# R7FA6T2BD register map
Vendor: Renesas Electronics Corporation; Series: RA6; File version: 1.30.01
CPU: CM33 r0p4, little endian, MPU, FPU, VTOR, 4 interrupt priority bits, 96 interrupts
Registers are 32-bit, read-write, reset 0x0 unless marked. A register's access mark holds for its fields unless they carry their own. Offsets are from the block's base; [hi:lo] are bit positions; {n}, {i} and the like mark numbered series.

## IIC_B0 — Inter-Integrated Circuit 0
Base 0x4011F000
Same registers: IIC_B1 0x4011F400
0x14 BCTL — Bus Control Register
  [31] BUSE — Bus Enable
    0=IIC bus operation is disabled; 1=IIC bus operation is enabled
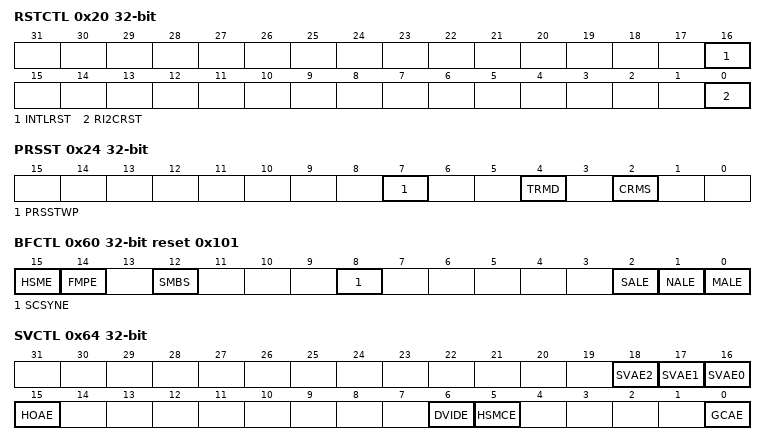
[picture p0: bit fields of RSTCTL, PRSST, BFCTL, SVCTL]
0x20 RSTCTL — Reset Control Register
  [16] INTLRST — Internal Software Reset
    0=Releases of some registers and internal state; 1=Resets of some registers and internal state
  [0] RI2CRST — IIC Software Reset
    0=Reset of all registers and internal state; 1=Releases of all registers and internal state
0x24 PRSST — Present State Register
  [7] PRSSTWP wo — Present State Write Protect
    0=CRMS bit is protected; 1=CRMS bit can be written when writing simultaneously with the value of the target bit
  [4] TRMD ro — Transmit/Receive Mode
    0=Receive mode; 1=Transmit mode
  [2] CRMS — Current Master
    0=The Master is not the Current Master, and must request and acquire bus ownership before initiating any transfer; 1=The Master is the Current Master, and as a result can initiate transfers
0x60 BFCTL reset 0x101 — Bus Function Control Register
  [15] HSME — High Speed Mode Enable
    0=Disable High Speed Mode; 1=Enable High Speed Mode
  [14] FMPE — Fast-mode Plus Enable
    0=No Fm+ slope control circuit uses for the SCLn pin and SDAn pin. (n = 0, 1); 1=An Fm+ slope control circuit uses for the SCLn pin and SDAn pin. (n = 0, 1)
  [12] SMBS — SMBus/I2C Bus Selection
    0=The I2C bus select; 1=The SMBus select
  [8] SCSYNE — SCL Synchronous Circuit Enable
    0=No SCL synchronous circuit uses; 1=An SCL synchronous circuit uses
  [2] SALE — Slave Arbitration-Lost Detection Enable
    0=Slave arbitration-lost detection disables; 1=Slave arbitration-lost detection enables
  [1] NALE — NACK Transmission Arbitration-Lost Detection Enable
    0=NACK transmission arbitration-lost detection disables; 1=NACK transmission arbitration-lost detection enables
  [0] MALE — Master Arbitration-Lost Detection Enable
    0=Master arbitration-lost detection disables. Disables the arbitration-lost detection function and does not clear the CRMS and TRMD bits in PRSST automatically when arbitration is lost.; 1=Master arbitration-lost detection enables. Enables the arbitration-lost detection function and clears the CRMS and TRMD bits in PRSST automatically when arbitration is lost.
0x64 SVCTL — Slave Control Register
  [18] SVAE2 — Slave Address Enable 2
    0=Slave 2 disables; 1=Slave 2 enables
  [17] SVAE1 — Slave Address Enable 1
    0=Slave 1 disables; 1=Slave 1 enables
  [16] SVAE0 — Slave Address Enable 0
    0=Slave 0 disables; 1=Slave 0 enables
  [15] HOAE — Host Address Enable
    0=Host address detection disables; 1=Host address detection enables
  [6] DVIDE — Device-ID Address Enable
    0=Device-ID address detection disables; 1=Device-ID address detection enables
  [5] HSMCE — Hs-mode Master Code Enable
    0=Hs-mode Master Code Detection disables; 1=Hs-mode Master Code Detection enables
  [0] GCAE — General Call Address Enable
    0=General call address detection disables; 1=General call address detection enables
0x70 REFCKCTL — Reference Clock Control Register
  [2:0] IREFCKS — Internal Reference Clock Selection
    0=IICCLK/1 clock; 1=IICCLK/2 clock; 2=IICCLK/4 clock; 3=IICCLK/8 clock; 4=IICCLK/16 clock; 5=IICCLK/32 clock; 6=IICCLK/64 clock; 7=IICCLK/128 clock
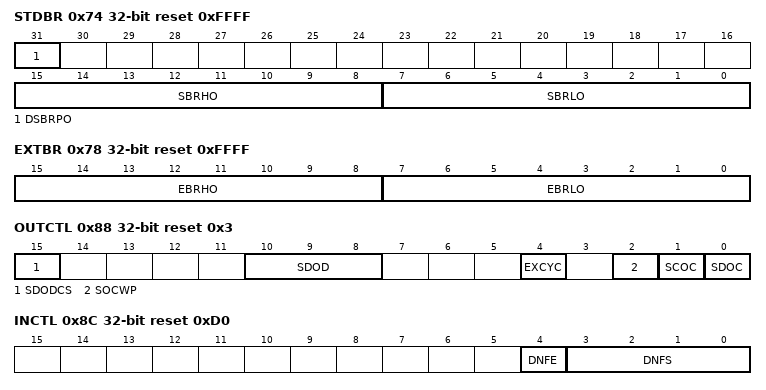
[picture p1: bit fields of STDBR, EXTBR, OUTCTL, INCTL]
0x74 STDBR reset 0xFFFF — Standard Bit Rate Register
  [31] DSBRPO — Double the Standard Bit Rate Period for Open-Drain
    0=The time period set for SBRHO[7:0] and SBRLO[7:0] is not doubled; 1=The time period set for SBRHO[7:0] and SBRLO[7:0] is doubled
  [15:8] SBRHO — Count value of the High-level period of SCL clock
  [7:0] SBRLO — Count value of the Low-level period of SCL clock
0x78 EXTBR reset 0xFFFF — Extended Bit Rate Register
  [15:8] EBRHO — Extended Bit Rate High-Level Period Open-Drain
  [7:0] EBRLO — Extended Bit Rate Low-Level Period Open-Drain
0x7C BFRECDT — Bus Free Condition Detection Time Register
  [8:0] FRECYC — Bus Free Condition Detection Cycle
0x88 OUTCTL reset 0x3 — Output Control Register
  [15] SDODCS — SDA Output Delay Clock Source Selection
    0=The internal reference clock (IICφ) is selected as the clock source of the SDA output delay counter; 1=The internal reference clock divided by 2 (IICφ/2) is selected as the clock source of the SDA output delay counter
  [10:8] SDOD — SDA Output Delay
    0=No output delay; 1=1 IICφ cycle (When OUTCTL.SDODCS = 0 (IICφ)) 1 or 2 IICφ cycles (When OUTCTL.SDODCS = 1 (IICφ/2)); 2=2 IICφ cycles (When OUTCTL.SDODCS = 0 (IICφ)) 3 or 4 IICφ cycles (When OUTCTL.SDODCS = 1 (IICφ/2)); 3=3 IICφ cycles (When OUTCTL.SDODCS = 0 (IICφ)) 5 or 6 IICφ cycles (When OUTCTL.SDODCS = 1 (IICφ/2)); 4=4 IICφ cycles (When OUTCTL.SDODCS = 0 (IICφ)) 7 or 8 IICφ cycles (When OUTCTL.SDODCS = 1 (IICφ/2)); 5=5 IICφ cycles (When OUTCTL.SDODCS = 0 (IICφ)) 9 or 10 IICφ cycles (When OUTCTL.SDODCS = 1 (IICφ/2)); 6=6 IICφ cycles (When OUTCTL.SDODCS = 0 (IICφ)) 11 or 12 IICφ cycles (When OUTCTL.SDODCS = 1 (IICφ/2)); 7=7 IICφ cycles (When OUTCTL.SDODCS = 0 (IICφ)) 13 or 14 IICφ cycles (When OUTCTL.SDODCS = 1 (IICφ/2))
  [4] EXCYC — Extra SCL Clock Cycle Output
    0=Does not output an extra SCL clock cycle (default); 1=Outputs an extra SCL clock cycle
  [2] SOCWP wo — SCL/SDA Output Control Write Protect
    0=Bits SCOC and SDOC are protected; 1=Bits SCOC and SDOC can be written (When writing simultaneously with the value of the target bit). This bit is read as 0.
  [1] SCOC — SCL Output Control
    0=IIC drives the SCLn pin low; 1=IIC releases the SCLn pin
  [0] SDOC — SDA Output Control
    0=IIC drives the SDAn pin low; 1=IIC releases the SDAn pin
0x8C INCTL reset 0xD0 — Input Control Register
  [4] DNFE — Digital Noise Filter Circuit Enable
    0=No digital noise filter circuit is used; 1=A digital noise filter circuit is used
  [3:0] DNFS — Digital Noise Filter Stage Selection
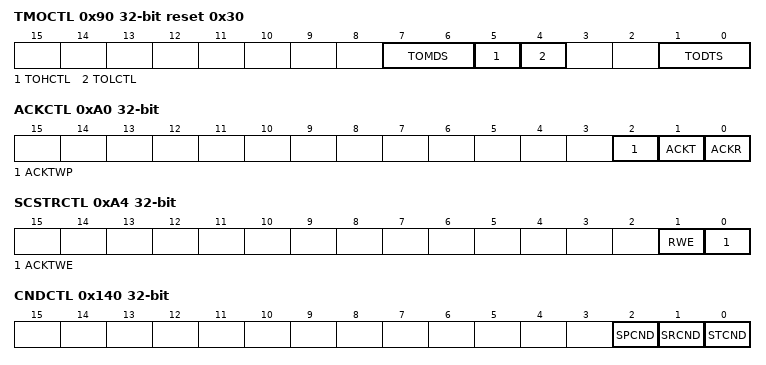
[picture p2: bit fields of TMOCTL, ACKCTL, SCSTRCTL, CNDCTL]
0x90 TMOCTL reset 0x30 — Timeout Control Register
  [7:6] TOMDS — Timeout Operation Mode Selection
    0=Timeout is detected during the following conditions: The bus is busy (BCST.BFREF = 0) in master mode.IIC’s own slave address is detected and the bus is busy in slave mode.The bus is free (BCST.BFREF = 1) while generation of a START condition is requested (CNDCTL.STCND = 1); 1=Timeout is detected while the bus is busy; 2=Timeout is detected while the bus is free; 3=Setting prohibited
  [5] TOHCTL — Timeout H Count Control
    0=Count is disabled while the SCLn line is at a high level; 1=Count is enabled while the SCLn line is at a high level
  [4] TOLCTL — Timeout L Count Control
    0=Count is disabled while the SCLn line is at a low level; 1=Count is enabled while the SCLn line is at a low level
  [1:0] TODTS — Timeout Detection Time Selection
    0=16bit-timeout; 1=14bit-timeout; 2=8bit-timeout; 3=6bit-timeout
0xA0 ACKCTL — Acknowledge Control Register
  [2] ACKTWP wo — ACKT Write Protect
    0=The ACKT bit are protected; 1=The ACKT bit can be written (when writing simultaneously with the value of the target bit). This bit is read as 0.
  [1] ACKT — Acknowledge Transmission
    0=A 0 is sent as the acknowledge bit (ACK transmission); 1=A 1 is sent as the acknowledge bit (NACK transmission)
  [0] ACKR ro — Acknowledge Reception
    0=A 0 is received as the acknowledge bit (ACK reception); 1=A 1 is received as the acknowledge bit (NACK reception)
0xA4 SCSTRCTL — SCL Stretch Control Register
  [1] RWE — Receive Wait Enable
    0=No WAIT (The period between ninth clock cycle and first clock cycle is not held low.); 1=WAIT (The period between ninth clock cycle and first clock cycle is held low.) Low-hold is released by reading NTDTBP0
  [0] ACKTWE — Acknowledge Transmission Wait Enable
    0=NTST.RDBFF0 is set at the rising edge of the ninth SCL clock cycle. (The SCLn line is not held low at the falling edge of the eighth clock cycle.); 1=NTST.RDBFF0 is set at the rising edge of the eighth SCL clock cycle. (The SCLn line is held low at the falling edge of the eighth clock cycle.) Low-hold is released by writing a value to the ACKCTL.ACKT bit.
0x140 CNDCTL — Condition Control Register
  [2] SPCND — STOP (P) Condition Issuance
    0=Does not request to issue a STOP condition; 1=Requests to issue a STOP condition
  [1] SRCND — Repeated START (Sr) Condition Issuance
    0=Does not request to issue a Repeated START condition; 1=Requests to issue a Repeated START condition
  [0] STCND — START (S) Condition Issuance
    0=Does not request to issue a START condition; 1=Requests to issue a START condition
0x158 NTDTBP0 — Normal Transfer Data Buffer Port Register 0
0x158 NTDTBP0_BY 8-bit (alternate view of NTDTBP0) — Normal Transfer Data Buffer Port Register 0
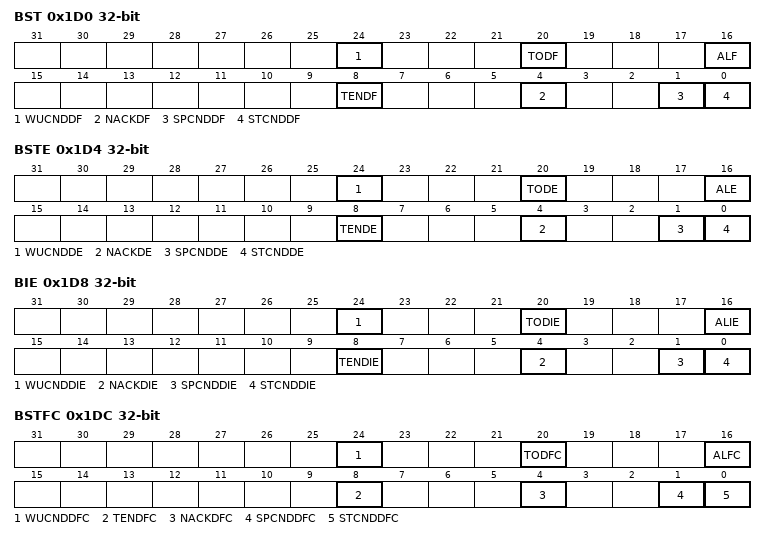
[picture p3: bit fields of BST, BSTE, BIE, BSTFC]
0x1D0 BST — Bus Status Register
  [24] WUCNDDF — Wake-Up Condition Detection Flag
    0=Wake-Up is not detected; 1=Wake-Up is detected
  [20] TODF — Timeout Detection Flag
    0=Timeout is not detected; 1=Timeout is detected
  [16] ALF — Arbitration Lost Flag
    0=Arbitration is not lost; 1=Arbitration is lost
  [8] TENDF — Transmit End Flag
    0=Data is being transmitted; 1=Data has been transmitted
  [4] NACKDF — NACK Detection Flag
    0=NACK is not detected; 1=NACK is detected
  [1] SPCNDDF — STOP Condition Detection Flag
    0=STOP condition is not detected; 1=STOP condition is detected
  [0] STCNDDF — START Condition Detection Flag
    0=START condition is not detected; 1=START condition is detected
0x1D4 BSTE — Bus Status Enable Register
  [24] WUCNDDE — Wake-up Condition Detection Enable
    0=Disables Wake-up Condition Detection Status logging; 1=Enables Wake-up Condition Detection Status logging
  [20] TODE — Timeout Detection Enable
    0=Disables Timeout Detection Interrupt Status logging; 1=Enables Timeout Detection Interrupt Status logging
  [16] ALE — Arbitration Lost Enable
    0=Disables Arbitration Lost Interrupt Status logging; 1=Enables Arbitration Lost Interrupt Status logging
  [8] TENDE — Transmit End Enable
    0=Disables Transmit End Interrupt Status logging; 1=Enables Transmit End Interrupt Status logging
  [4] NACKDE — NACK Detection Enable
    0=Disables NACK Detection Interrupt Status logging; 1=Enables NACK Detection Interrupt Status logging
  [1] SPCNDDE — STOP Condition Detection Enable
    0=Disables STOP condition Detection Interrupt Status logging; 1=Enables STOP condition Detection Interrupt Status logging
  [0] STCNDDE — START Condition Detection Enable
    0=Disables START condition Detection Interrupt Status logging; 1=Enables START condition Detection Interrupt Status logging
0x1D8 BIE — Bus Interrupt Enable Register
  [24] WUCNDDIE — Wake-Up Condition Detection Interrupt Enable
    0=Disables Wake-Up Condition Detection Interrupt Signal; 1=Enables Wake-Up Condition Detection Interrupt Signal
  [20] TODIE — Timeout Detection Interrupt Enable
    0=Disables Timeout Detection Interrupt Signal; 1=Enables Timeout Detection Interrupt Signal
  [16] ALIE — Arbitration Lost Interrupt Enable
    0=Disables Arbitration Lost Interrupt Signal; 1=Enables Arbitration Lost Interrupt Signal
  [8] TENDIE — Transmit End Interrupt Enable
    0=Disables Transmit End Interrupt Signal; 1=Enables Transmit End Interrupt Signal
  [4] NACKDIE — NACK Detection Interrupt Enable
    0=Disables NACK Detection Interrupt Signal; 1=Enables NACK Detection Interrupt Signal
  [1] SPCNDDIE — STOP Condition Detection Interrupt Enable
    0=Disables STOP condition Detection Interrupt Signal; 1=Enables STOP condition Detection Interrupt Signal
  [0] STCNDDIE — START Condition Detection Interrupt Enable
    0=Disables START condition Detection Interrupt Signal; 1=Enables START condition Detection Interrupt Signal
0x1DC BSTFC — Bus Status Force Register
  [24] WUCNDDFC wo — Wake-Up Condition Detection Force
    0=Not Force Wake-Up Condition Detection Interrupt for software testing; 1=Force Wake-Up Condition Detection Interrupt for software testing
  [20] TODFC wo — Timeout Detection Force
    0=Not Force Timeout Detection Interrupt for software testing; 1=Force Timeout Detection Interrupt for software testing
  [16] ALFC wo — Arbitration Lost Force
    0=Not Force Arbitration Lost Interrupt for software testing; 1=Force Arbitration Lost Interrupt for software testing
  [8] TENDFC wo — Transmit End Force
    0=Not Force Transmit End Interrupt for software testing; 1=Force Transmit End Interrupt for software testing
  [4] NACKDFC wo — NACK Detection Force
    0=Not Force NACK Detection Interrupt for software testing; 1=Force NACK Detection Interrupt for software testing
  [1] SPCNDDFC wo — STOP condition Detection Force
    0=Not Force STOP condition Detection Interrupt for software testing; 1=Force STOP condition Detection Interrupt for software testing
  [0] STCNDDFC wo — START condition Detection Force
    0=Not Force START condition Detection Interrupt for software testing; 1=Force START condition Detection Interrupt for software testing
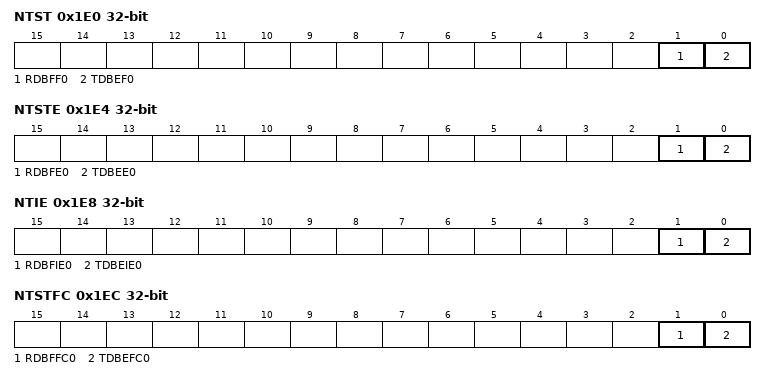
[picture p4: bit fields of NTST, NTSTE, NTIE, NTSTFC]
0x1E0 NTST — Normal Transfer Status Register
  [1] RDBFF0 — Normal Receive Data Buffer Full Flag 0
    0=Normal Receive Data Buffer0 contains no receive data; 1=Normal Receive Data Buffer0 contains receive data
  [0] TDBEF0 — Normal Transmit Data Buffer Empty Flag 0
    0=Normal Transmit Data Buffer 0 contains transmit data; 1=Normal Transmit Data Buffer 0 contains no transmit data
0x1E4 NTSTE — Normal Transfer Status Enable Register
  [1] RDBFE0 — Normal Receive Data Buffer Full Enable 0
    0=Disables Rx0 Data Buffer Full Interrupt Status logging; 1=Enables Rx0 Data Buffer Full Interrupt Status logging
  [0] TDBEE0 — Normal Transmit Data Buffer Empty Enable 0
    0=Disables Tx0 Data Buffer Empty Interrupt Status logging; 1=Enables Tx0 Data Buffer Empty Interrupt Status logging
0x1E8 NTIE — Normal Transfer Interrupt Enable Register
  [1] RDBFIE0 — Normal Receive Data Buffer Full Interrupt Enable 0
    0=Disables Rx0 Data Buffer Full Interrupt Signal; 1=Enables Rx0 Data Buffer Full Interrupt Signal
  [0] TDBEIE0 — Normal Transmit Data Buffer Empty Interrupt Enable 0
    0=Disables Tx0 Data Buffer Empty Interrupt Signal; 1=Enables Tx0 Data Buffer Empty Interrupt Signal
0x1EC NTSTFC wo — Normal Transfer Status Force Register
  [1] RDBFFC0 — Normal Receive Data Buffer Full Force 0
    0=Not Force Rx0 Data Buffer Full Interrupt for software testing; 1=Force Rx0 Data Buffer Full Interrupt for software testing
  [0] TDBEFC0 — Normal Transmit Data Buffer Empty Force 0
    0=Not Force Tx0 Data Buffer Empty Interrupt for software testing; 1=Force Tx0 Data Buffer Empty Interrupt for software testing
0x210 BCST ro — Bus Condition Status Register
  [0] BFREF — Bus Free Detection Flag
    0=Have not Detected Bus Free; 1=Have Detected Bus Free
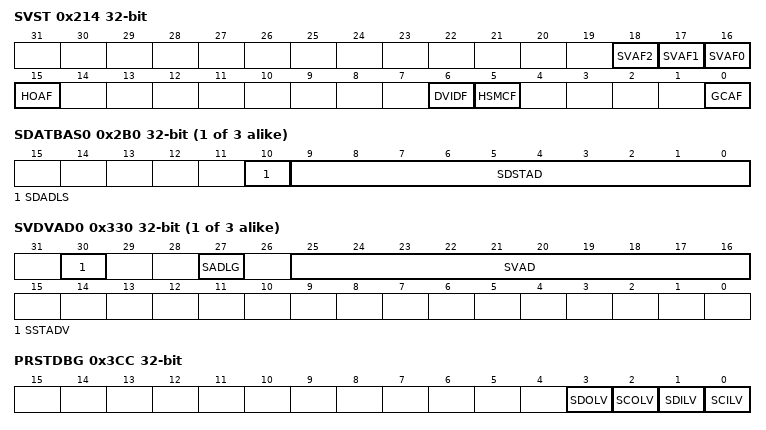
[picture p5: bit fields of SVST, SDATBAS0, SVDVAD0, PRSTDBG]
0x214 SVST — Slave Status Register
  [18] SVAF2 — Slave Address Detection Flag 2
    0=Slave 2 does not detect; 1=Slave 2 detect
  [17] SVAF1 — Slave Address Detection Flag 1
    0=Slave 1 does not detect; 1=Slave 1 detect
  [16] SVAF0 — Slave Address Detection Flag 0
    0=Slave 0 does not detect; 1=Slave 0 detect
  [15] HOAF — Host Address Detection Flag
    0=Host address does not detect; 1=Host address detects. This bit set to 1 when the received slave address matches the host address (0001 000).
  [6] DVIDF — Device-ID Address Detection Flag
    0=Device-ID command does not detect; 1=Device-ID command detects. This bit set to 1 when the first frame received immediately after a START condition is detected matches a value of (device ID (1111 100) + 0[W]).
  [5] HSMCF — Hs-mode Master Code Detection Flag
    0=Hs-mode Master Code does not detect; 1=Hs-mode Master Code detects
  [0] GCAF — General Call Address Detection Flag
    0=General call address does not detect; 1=General call address detects
{0x2B0+4i} SDATBAS{i} (i=0..2) — Slave Device Address Table Basic Register {i}
  [10] SDADLS — Slave Device Address Length Selection
    0=Slave Device address length 7 bits selected; 1=Slave Device address length 10 bits selected. (I2C device only)
  [9:0] SDSTAD — Slave Device Static Address
{0x330+4i} SVDVAD{i} (i=0..2) ro — Slave Device Address Register {i}
  [30] SSTADV — Slave Static Address Valid
    0=Slave address is disabled; 1=Slave address is enabled
  [27] SADLG — Slave Address Length
    0=The 7-bit address format is selected; 1=The 10-bit address format is selected
  [25:16] SVAD — Slave Address
0x380 BITCNT ro — Bit Count Register
  [4:0] BCNT — Bit Counter
0x3CC PRSTDBG ro — Present State Debug Register
  [3] SDOLV — SDA Output Level
    0=IIC has driven the SDA pin low; 1=IIC has released the SDA pin
  [2] SCOLV — SCL Output Level
    0=IIC has driven the SCL pin low; 1=IIC has released the SCL pin
  [1] SDILV — SDA Line Signal Level
  [0] SCILV — SCL Line Signal Level
